# DA14531 register map
Vendor: Dialog; Series: DA14531; File version: 1.2
CPU: CM0 r1p0, little endian, MPU, FPU, 3 interrupt priority bits
Registers are 16-bit, read-write, reset 0x0 unless marked. A register's access mark holds for its fields unless they carry their own. Offsets are from the block's base; lines under a group give offsets from that group; [hi:lo] are bit positions; {n}, {i} and the like mark numbered series; 'fields as' and 'values as' point back to an identical list; <NAME> marks a mode.

## Memory map
0x07F40000 OTPC size 0x24 — OTPC registers
0x40000000 BLE size 0x214 — BLE registers
0x40001000 RFCU size 0xBC — RFCU registers
0x40001200 RFCU_POWER size 0x190 — RFCU_POWER registers
0x40003000 adplldig size 0x98 — adplldig registers
0x40080000 PATCH size 0xD0 — PATCH registers
0x50000000 CRG_TOP size 0x56 — CRG_TOP registers
0x50000100 WKUP size 0x10 — WKUP registers
0x50000200 QUADEC size 0xE — QUADEC registers
0x50000300 CRG_AON size 0xF2 — CRG_AON registers
0x50001000 UART size 0x100 — UART registers
0x50001100 UART2 size 0x100 — UART2 registers
0x50001200 SPI size 0x32 — SPI registers
0x50001300 I2C size 0x100 — I2C registers
0x50001400 KBRD size 0x16 — KBRD registers
0x50001500 GPADC size 0x20 — GPADC registers
0x50001600 ANAMISC size 0x8 — ANAMISC registers
0x50003000 GPIO size 0x42 — GPIO registers
0x50003100 SYS_WDOG size 0x4 — SYS_WDOG registers
0x50003200 CHIP_VERSION size 0xFE — CHIP_VERSION registers
0x50003300 GPREG size 0xE — GPREG registers
0x50003400 TIMER0 size 0x24 — TIMER0 registers
0x50003500 RFMON size 0x16 — RFMON registers
0x50003700 MBIST_SRAM12 size 0x8 — MBIST_SRAM12 registers
0x50003800 MBIST_SRAM3 size 0x8 — MBIST_SRAM3 registers
0x50004000 TIMER1 size 0x18 — TIMER1 registers
0x50004100 RTC size 0x34 — RTC registers
0x50004200 CRG_TIM size 0x50 — CRG_TIM registers
0xE000E010 SysTick size 0x11 — Cortex M0 SysTick registers
0xE000E100 NVIC size 0x321 — Cortex M0 NVIC registers
0xE000ED00 SCB size 0x29 — Cortex M0 SCB registers

## SCB — Cortex M0 SCB registers
Base 0xE000ED00
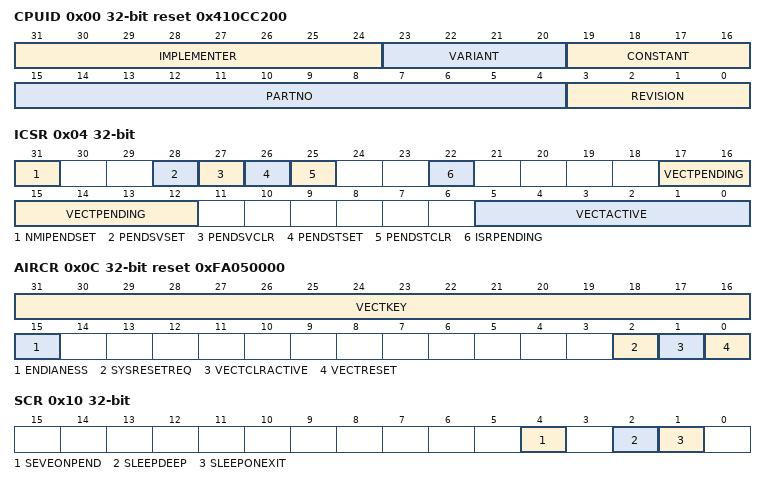
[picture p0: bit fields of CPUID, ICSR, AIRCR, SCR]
0x00 CPUID 32-bit reset 0x410CC200 — CPUID base register
  [31:24] IMPLEMENTER ro — IMPLEMENTER[7:0] bits (Implementer code)
  [23:20] VARIANT ro — VARIANT[3:0] bits (Variant number)
  [19:16] CONSTANT ro — CONSTANT[3:0] bits (Reads as 0xF)
  [15:4] PARTNO ro — PARTNO[11:0] bits (Part number of the processor core)
  [3:0] REVISION ro — REVISION[3:0] bits (Revision number)
0x04 ICSR 32-bit — Interrupt control and state register
  [31] NMIPENDSET — NMI set-pending bit
  [28] PENDSVSET — PendSV set-pending bit
  [27] PENDSVCLR — PendSV clear-pending bit
  [26] PENDSTSET — SysTick exception set-pending bit
  [25] PENDSTCLR — SysTick exception clear-pending bit
  [22] ISRPENDING — Interrupt pending flag, excluding NMI and Faults
  [17:12] VECTPENDING — VECTPENDING[5:0] bits (Pending vector)
  [5:0] VECTACTIVE — VECTACTIVE[5:0] bits (Active vector)
0x0C AIRCR 32-bit ro reset 0xFA050000 — Application interrupt and reset control register
  [31:16] VECTKEY — VECTKEY[15:0] bits (Register key)
  [15] ENDIANESS — Data endianness bit
  [2] SYSRESETREQ — System reset request
  [1] VECTCLRACTIVE — Reserved for Debug use
  [0] VECTRESET — Reserved for Debug use
0x10 SCR 32-bit — System control register
  [4] SEVEONPEND — Send event on pending bit
  [2] SLEEPDEEP — Controls whether the processor uses sleep or deep sleep
  [1] SLEEPONEXIT — Configures sleep-on-exit when returning from Handler mode to Thread mode
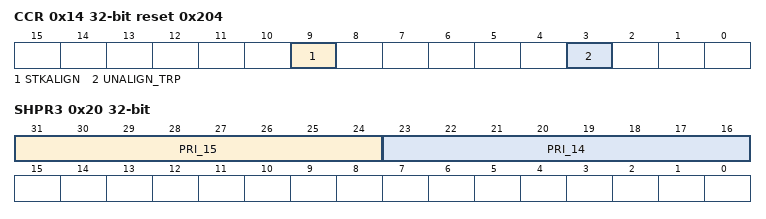
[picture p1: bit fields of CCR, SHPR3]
0x14 CCR 32-bit reset 0x204 — Configuration and control register
  [9] STKALIGN — Configures stack alignment on exception entry
  [3] UNALIGN_TRP — Enables unaligned access traps
0x1C SHPR2 32-bit — System handler priority register 2
  [31:24] PRI_11 — PRI_11[7:0] bits (Priority of system handler 11, SVCall)
0x20 SHPR3 32-bit — System handler priority register 3
  [31:24] PRI_15 — PRI_15[7:0] bits (Priority of system handler 15, SysTick exception)
  [23:16] PRI_14 — PRI_14[7:0] bits (Priority of system handler 14, PendSV)

## Licence text in the file
Copyright (C) 2019 Dialog Semiconductor. This computer program includes Confidential, Proprietary Information of Dialog Semiconductor. All Rights Reserved. . Dialog GmbH (DLG) is supplying this software for use with Cortex-M processor based microcontroller, but can be equally used for other suitable processor architectures. This file can be freely distributed. Modifications to this file shall be clearly marked. . THIS SOFTWARE IS PROVIDED AS IS . NO WARRANTIES, WHETHER EXPRESS, IMPLIED. OR STATUTORY, INCLUDING, BUT NOT LIMITED TO, IMPLIED WARRANTIES OF. MERCHANTABILITY AND FITNESS FOR A PARTICULAR PURPOSE APPLY TO THIS SOFTWARE. ARM SHALL NOT, IN ANY CIRCUMSTANCES, BE LIABLE FOR SPECIAL, INCIDENTAL, OR. CONSEQUENTIAL DAMAGES, FOR ANY REASON WHATSOEVER.
